# CY8C5868AXI_LP032 register map
File version: 0.1
CY8C58LP
Registers are 8-bit, read-write, no defined reset value unless marked. A register's access mark holds for its fields unless they carry their own. Offsets are from the block's base; lines under a group give offsets from that group; [hi:lo] are bit positions; {n}, {i} and the like mark numbered series; 'fields as' and 'values as' point back to an identical list; <NAME> marks a mode.

## Memory map
0x00000000 VDAC8
0x00000000 USBFS

## VDAC8
Base 0x00000000
0x400043A8 VDAC8_PM_ACT_CFG — Active Power Mode Configuration Register 8
  [4:0] en_dac — Enable DAC block(s). Populated subsystems are counted from the LSB
0x400043B8 VDAC8_PM_STBY_CFG — Standby Power Mode Configuration Register 8
  fields as VDAC8_PM_ACT_CFG
0x40004609 VDAC8_TR
  [7:0] tr — 8 Calibration bits
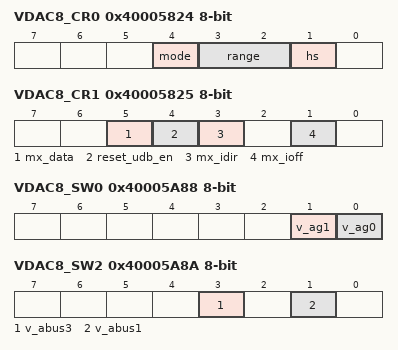
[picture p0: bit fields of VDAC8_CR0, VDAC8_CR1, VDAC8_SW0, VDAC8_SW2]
0x40005824 VDAC8_CR0 — DAC Block Control Register 0
  [4] mode ro — Mode Bit
    0=DAC_MODE_V (voltage DAC); 1=DAC_MODE_I (current DAC)
  [3:2] range — Ranges for mode=0 (VDAC) and mode=1 (IDAC)
    0=DAC_RANGE_0 (x0=0V to 4*vref (1.024V); 0 to 31.875uA); 1=DAC_RANGE_1 (x1=0V to 16*vref (4.096V); 0 to 255uA); 2=DAC_RANGE_2 (x0=0V to 4*vref (1.024V); 0 to 2.040mA); 3=DAC_RANGE_3 (x1=0V to 16*vref (4.096V); not used)
  [1] hs — High Speed Bit
    0=DAC_HS_LOWPOWER (regular (low power)); 1=DAC_HS_HIGHSPEED (high speed (higher power))
0x40005825 VDAC8_CR1 — DAC Block Control Register 1
  [5] mx_data — Select DATA source
    0=MX_DATA_REG (Select register source (DACxn_D)); 1=MX_DATA_UDB (Select UDB source)
  [4] reset_udb_en — DAC reset enable
    0=RESET_UDB_EN_DISABLE (Disable DAC Reset Source from UDB (System reset always resets)); 1=RESET_UDB_EN_ENABLE (Enable DAC Reset Source from UDB)
  [3] mx_idir — Mux selection for DAC current direction control
    0=MX_IDIR_REG (Register source idirbit selected); 1=MX_IDIR_UDB (UDB ictrl selected)
  [1] mx_ioff — Mux selection for DAC current off control
    0=MX_IOFF_REG (Register source ioffbit selected); 1=MX_IOFF_UDB (UDB ictrl selected)
0x40005A88 VDAC8_SW0 — DAC Analog Routing Register 0
  [1] v_ag1 — Connect voltage output to analog global of same side
    0=AG_NC (not connected); 1=AG_CONNECTED (Connect to Analog Global)
  [0] v_ag0 — Connect voltage output to analog global of same side
    values as v_ag1
0x40005A8A VDAC8_SW2 — DAC Analog Routing Register 2
  [3] v_abus3 — Connect voltage output to analog (local) bus of the same side
    0=ABUS_NC (not connected); 1=ABUS_CONNECTED (Connect to Analog (local) Bus)
  [1] v_abus1 — Connect voltage output to analog (local) bus of the same side
    values as v_abus3
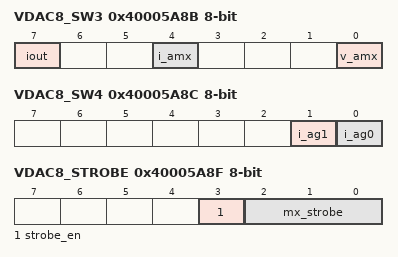
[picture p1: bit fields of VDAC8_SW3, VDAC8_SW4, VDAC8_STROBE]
0x40005A8B VDAC8_SW3 — DAC Analog Routing Register 3
  [7] iout — Connect current output to pad
    0=IOUT_NC (not connected); 1=IOUT_CONNECT (Connect to pad)
  [4] i_amx — Connect current output to Analog Mux Bus
    0=AMX_NC (not connected); 1=AMX_CONNECTED (Connect to AMUXBUS)
  [0] v_amx — Connect voltage output to Analog Mux Bus
    values as i_amx
0x40005A8C VDAC8_SW4 — DAC Analog Routing Register 4
  [1] i_ag1 — Connect current output to analog global of same side
    values as VDAC8_SW0.v_ag1
  [0] i_ag0 — Connect current output to analog global of same side
    values as VDAC8_SW0.v_ag1
0x40005A8F VDAC8_STROBE — DAC Strobe Register
  [3] strobe_en — Strobe gating control (See mx_strobe==3'h0)
    0=disable strobe; 1=enable strobe
  [2:0] mx_strobe — Strobe source selection
    0=MX_STROBE_BUSWRITE (Select bus write strobe source (Enable gater regardless of strobe_en setting)); 1=MX_STROBE_UDB_SRC (Select UDB strobe source); 2=MX_STROBE_NC_2 (NC); 3=MX_STROBE_NC_3 (NC); {v}=MX_STROBE_CLK_A{v-4}_DIG (Select clk_a{v-4}_dig) (v=4..7)
0x40005B81 VDAC8_DATA — DAC Data Register
  [7:0] data — 8 DAC Data bits

## USBFS
Base 0x00000000
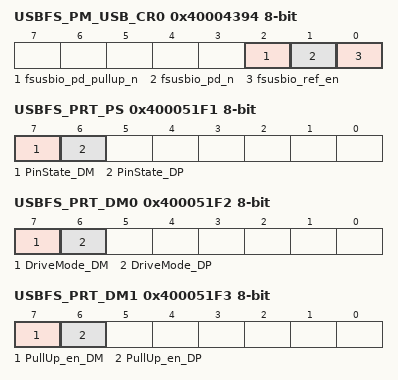
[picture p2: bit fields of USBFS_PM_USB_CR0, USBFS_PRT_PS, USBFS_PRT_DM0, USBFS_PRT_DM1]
0x40004394 USBFS_PM_USB_CR0 — USB Power Mode Control Register 0
  [2] fsusbio_pd_pullup_n, [1] fsusbio_pd_n, [0] fsusbio_ref_en
0x400043A5 USBFS_PM_ACT_CFG — Active Power Mode Configuration Register
0x400043B5 USBFS_PM_STBY_CFG — Standby Power Mode Configuration Register
0x400051F1 USBFS_PRT_PS — Port Pin State Register
  [7] PinState_DM ro, [6] PinState_DP ro
0x400051F2 USBFS_PRT_DM0 — Port Drive Mode Register
  [7] DriveMode_DM, [6] DriveMode_DP
0x400051F3 USBFS_PRT_DM1 — Port Drive Mode Register
  [7] PullUp_en_DM, [6] PullUp_en_DP
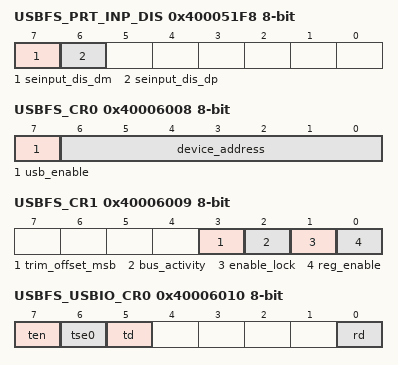
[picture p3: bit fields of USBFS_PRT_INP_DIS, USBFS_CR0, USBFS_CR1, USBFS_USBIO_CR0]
0x400051F8 USBFS_PRT_INP_DIS — Input buffer disable override
  [7] seinput_dis_dm, [6] seinput_dis_dp
0x40006000 USBFS_EP0_DR0 — bmRequestType
0x40006001 USBFS_EP0_DR1 — bRequest
0x40006002 USBFS_EP0_DR2 — wValueLo
0x40006003 USBFS_EP0_DR3 — wValueHi
0x40006004 USBFS_EP0_DR4 — wIndexLo
0x40006005 USBFS_EP0_DR5 — wIndexHi
0x40006006 USBFS_EP0_DR6 — lengthLo
0x40006007 USBFS_EP0_DR7 — lengthHi
0x40006008 USBFS_CR0 — USB Control Register 0
  [7] usb_enable, [6:0] device_address ro
0x40006009 USBFS_CR1 — USB Control Register 1
  [3] trim_offset_msb, [2] bus_activity, [1] enable_lock, [0] reg_enable
{0x40005FFE+0x10*i} USBFS_SIE_EP{i}_CR0 (i=1..8) — The Endpoint{i} Control Register
0x40006010 USBFS_USBIO_CR0 — USBIO Control Register 0
  [7] ten, [6] tse0, [5] td, [0] rd ro
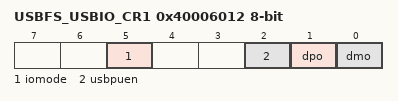
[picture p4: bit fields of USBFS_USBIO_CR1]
0x40006012 USBFS_USBIO_CR1 — USBIO Control Register 1
  [5] iomode, [2] usbpuen, [1] dpo ro, [0] dmo ro
0x4000608C USBFS_BUF_SIZE — Dedicated Endpoint Buffer Size Register
0x4000608E USBFS_EP_ACTIVE — Endpoint Active Indication Register
0x4000608F USBFS_EP_TYPE — Endpoint Type (IN/OUT) Indication
0x4000609D USBFS_USB_CLK_EN — USB Block Clock Enable Register
